VERSION ""

NS_ :

BS_:

BU_: data_logger drive_controller kart_machine_manager motec_ecu

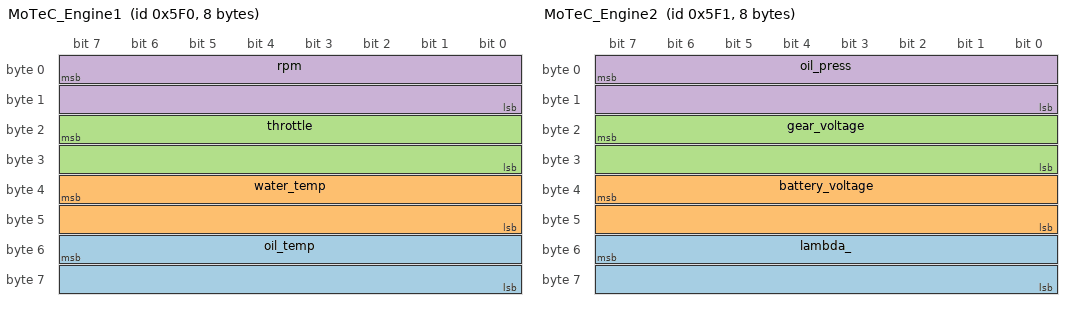
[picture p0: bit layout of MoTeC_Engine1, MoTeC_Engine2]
BO_ 1520 MoTeC_Engine1: 8 motec_ecu
 SG_ oil_temp : 55|16@0+ (0.1,0) [0|0] "degC"  kart_machine_manager
 SG_ water_temp : 39|16@0+ (0.1,0) [0|0] "degC"  kart_machine_manager
 SG_ throttle : 23|16@0+ (0.1,0) [0|0] "%"  kart_machine_manager
 SG_ rpm : 7|16@0+ (1,0) [0|0] "rpm"  kart_machine_manager

BO_ 1521 MoTeC_Engine2: 8 motec_ecu
 SG_ lambda_ : 55|16@0+ (0.001,0) [0|0] ""  kart_machine_manager,drive_controller
 SG_ battery_voltage : 39|16@0+ (0.01,0) [0|0] "V"  kart_machine_manager,drive_controller
 SG_ gear_voltage : 23|16@0+ (0.001,0) [0|0] "V"  kart_machine_manager,drive_controller
 SG_ oil_press : 7|16@0+ (0.1,0) [0|0] ""  kart_machine_manager,drive_controller

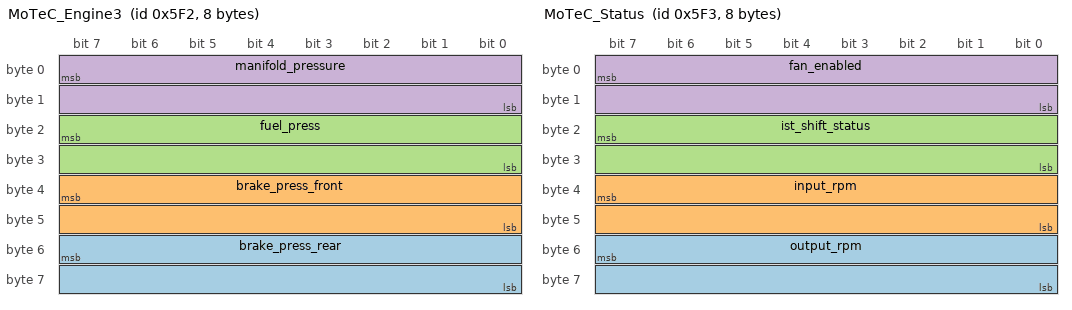
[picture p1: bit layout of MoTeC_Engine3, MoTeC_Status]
BO_ 1522 MoTeC_Engine3: 8 motec_ecu
 SG_ brake_press_rear : 55|16@0+ (0.1,0) [0|0] ""  kart_machine_manager
 SG_ brake_press_front : 39|16@0+ (0.1,0) [0|0] ""  kart_machine_manager
 SG_ fuel_press : 23|16@0+ (0.1,0) [0|0] ""  kart_machine_manager
 SG_ manifold_pressure : 7|16@0+ (0.1,0) [0|0] "kPa"  kart_machine_manager

BO_ 1523 MoTeC_Status: 8 motec_ecu
 SG_ output_rpm : 55|16@0+ (1,0) [0|0] "rpm"  kart_machine_manager
 SG_ input_rpm : 39|16@0+ (1,0) [0|0] "rpm"  kart_machine_manager
 SG_ ist_shift_status : 23|16@0+ (1,0) [0|0] ""  kart_machine_manager
 SG_ fan_enabled : 7|16@0+ (1,0) [0|0] ""  kart_machine_manager

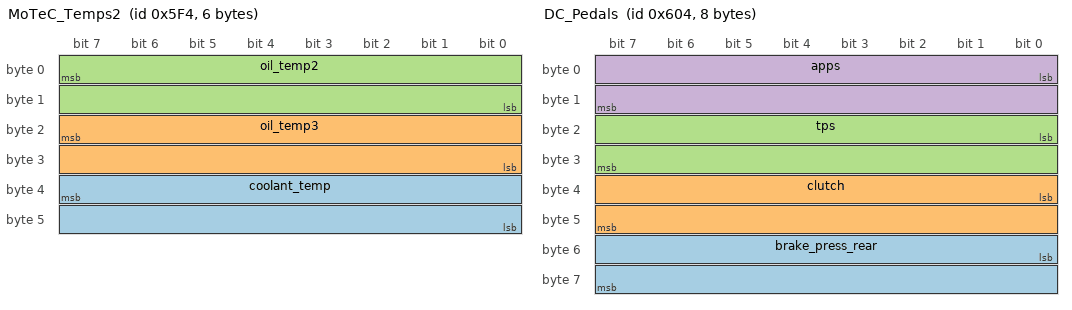
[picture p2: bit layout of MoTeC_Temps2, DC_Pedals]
BO_ 1524 MoTeC_Temps2: 6 motec_ecu
 SG_ coolant_temp : 39|16@0+ (0.1,0) [0|0] "degC"  kart_machine_manager
 SG_ oil_temp3 : 23|16@0+ (0.1,0) [0|0] "degC"  kart_machine_manager
 SG_ oil_temp2 : 7|16@0+ (0.1,0) [0|0] "degC"  kart_machine_manager

BO_ 1536 DC_GyroXY: 8 drive_controller
 SG_ gyro_y : 32|32@1+ (1,0) [0|0] "dps"  kart_machine_manager
 SG_ gyro_x : 0|32@1+ (1,0) [0|0] "dps"  kart_machine_manager

BO_ 1537 DC_GyroZGear: 5 drive_controller
 SG_ gear : 32|8@1+ (1,0) [0|0] ""  kart_machine_manager
 SG_ gyro_z : 0|32@1+ (1,0) [0|0] "dps"  kart_machine_manager

BO_ 1538 DC_AccelXY: 8 drive_controller
 SG_ accel_y : 32|32@1+ (1,0) [0|0] "mg"  kart_machine_manager
 SG_ accel_x : 0|32@1+ (1,0) [0|0] "mg"  kart_machine_manager

BO_ 1539 DC_AccelZ: 4 drive_controller
 SG_ accel_z : 0|32@1+ (1,0) [0|0] "mg"  kart_machine_manager

BO_ 1540 DC_Pedals: 8 drive_controller
 SG_ brake_press_rear : 48|16@1+ (0.1,0) [0|0] "psi"  kart_machine_manager
 SG_ clutch : 32|16@1+ (0.01,0) [0|0] "%"  kart_machine_manager
 SG_ tps : 16|16@1+ (0.01,0) [0|0] "%"  kart_machine_manager
 SG_ apps : 0|16@1+ (0.01,0) [0|0] "%"  kart_machine_manager

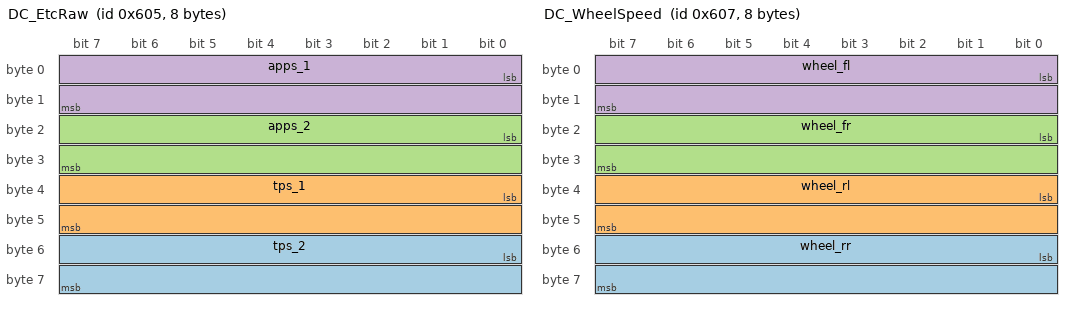
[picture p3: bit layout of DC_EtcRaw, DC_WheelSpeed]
BO_ 1541 DC_EtcRaw: 8 drive_controller
 SG_ tps_2 : 48|16@1+ (7.8125e-05,0) [0|0] "V"  kart_machine_manager
 SG_ tps_1 : 32|16@1+ (7.8125e-05,0) [0|0] "V"  kart_machine_manager
 SG_ apps_2 : 16|16@1+ (7.8125e-05,0) [0|0] "V"  kart_machine_manager
 SG_ apps_1 : 0|16@1+ (7.8125e-05,0) [0|0] "V"  kart_machine_manager

BO_ 1542 DC_StrokeRear: 4 drive_controller
 SG_ stroke_rr : 16|16@1+ (0.01,0) [0|0] "V"  kart_machine_manager
 SG_ stroke_rl : 0|16@1+ (0.01,0) [0|0] "V"  kart_machine_manager

BO_ 1543 DC_WheelSpeed: 8 drive_controller
 SG_ wheel_rr : 48|16@1+ (0.01,0) [0|0] "km/h"  kart_machine_manager
 SG_ wheel_rl : 32|16@1+ (0.01,0) [0|0] "km/h"  kart_machine_manager
 SG_ wheel_fr : 16|16@1+ (0.01,0) [0|0] "km/h"  kart_machine_manager
 SG_ wheel_fl : 0|16@1+ (0.01,0) [0|0] "km/h"  kart_machine_manager

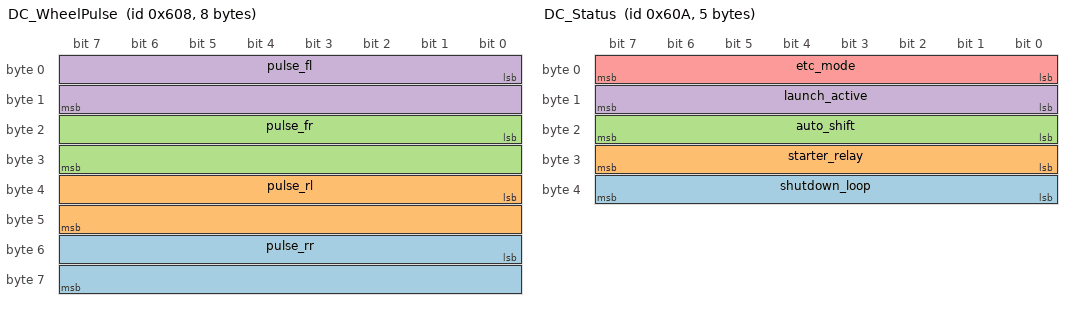
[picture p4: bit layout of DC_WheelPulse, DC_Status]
BO_ 1544 DC_WheelPulse: 8 drive_controller
 SG_ pulse_rr : 48|16@1+ (1,0) [0|0] "count"  kart_machine_manager
 SG_ pulse_rl : 32|16@1+ (1,0) [0|0] "count"  kart_machine_manager
 SG_ pulse_fr : 16|16@1+ (1,0) [0|0] "count"  kart_machine_manager
 SG_ pulse_fl : 0|16@1+ (1,0) [0|0] "count"  kart_machine_manager

BO_ 1545 DC_Engine: 4 drive_controller
 SG_ clutch_rpm : 16|16@1+ (1,0) [0|0] "rpm"  kart_machine_manager
 SG_ engine_rpm : 0|16@1+ (1,0) [0|0] "rpm"  kart_machine_manager

BO_ 1546 DC_Status: 5 drive_controller
 SG_ shutdown_loop : 32|8@1+ (1,0) [0|0] ""  kart_machine_manager
 SG_ starter_relay : 24|8@1+ (1,0) [0|0] ""  kart_machine_manager
 SG_ auto_shift : 16|8@1+ (1,0) [0|0] ""  kart_machine_manager
 SG_ launch_active : 8|8@1+ (1,0) [0|0] ""  kart_machine_manager
 SG_ etc_mode : 0|8@1+ (1,0) [0|0] ""  kart_machine_manager

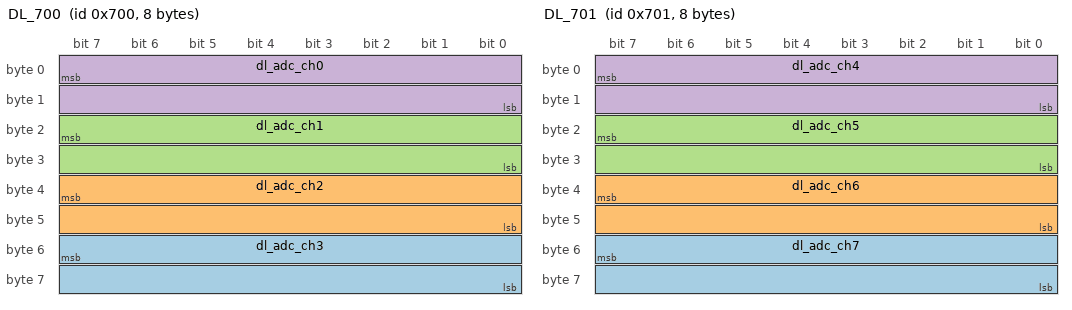
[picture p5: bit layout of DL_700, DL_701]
BO_ 1792 DL_700: 8 data_logger
 SG_ dl_adc_ch3 : 55|16@0+ (7.8125e-05,0) [0|0] "V"  kart_machine_manager
 SG_ dl_adc_ch2 : 39|16@0+ (7.8125e-05,0) [0|0] "V"  kart_machine_manager
 SG_ dl_adc_ch1 : 23|16@0+ (7.8125e-05,0) [0|0] "V"  kart_machine_manager
 SG_ dl_adc_ch0 : 7|16@0+ (7.8125e-05,0) [0|0] "V"  kart_machine_manager

BO_ 1793 DL_701: 8 data_logger
 SG_ dl_adc_ch7 : 55|16@0+ (7.8125e-05,0) [0|0] "V"  kart_machine_manager
 SG_ dl_adc_ch6 : 39|16@0+ (7.8125e-05,0) [0|0] "V"  kart_machine_manager
 SG_ dl_adc_ch5 : 23|16@0+ (7.8125e-05,0) [0|0] "V"  kart_machine_manager
 SG_ dl_adc_ch4 : 7|16@0+ (7.8125e-05,0) [0|0] "V"  kart_machine_manager

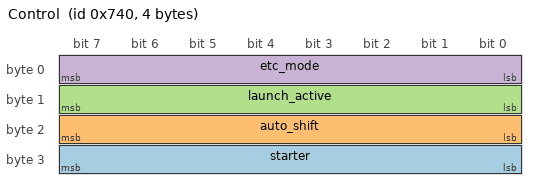
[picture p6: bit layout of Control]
BO_ 1856 Control: 4 data_logger
 SG_ starter : 31|8@0+ (1,0) [0|0] ""  drive_controller,kart_machine_manager
 SG_ auto_shift : 23|8@0+ (1,0) [0|0] ""  drive_controller,kart_machine_manager
 SG_ launch_active : 15|8@0+ (1,0) [0|0] ""  drive_controller,kart_machine_manager
 SG_ etc_mode : 7|8@0+ (1,0) [0|0] ""  drive_controller,kart_machine_manager

BO_ 1857 Shift: 2 data_logger
 SG_ shift_down : 15|8@0+ (1,0) [0|0] ""  drive_controller,kart_machine_manager
 SG_ shift_up : 7|8@0+ (1,0) [0|0] ""  drive_controller,kart_machine_manager

CM_ BU_ data_logger "kmm M コア (Cortex-M4, data-logger-zephyr apps/can-gw)。ADS8688 ADC とコックピットスイッチを送信。Linux 向け CAN ゲートウェイ。";
CM_ BU_ drive_controller "駆動系ECU (Teensy 4.1, 車両後方)。ETC/クラッチ/シフト/セルモーター/ブレーキランプ制御。IMU・APPS/TPS・後方センサー・車輪速・自身の状態を送信。";
CM_ BU_ kart_machine_manager "kmm A コア (Linux)。M コアのゲートウェイ経由で CAN 全受信。インパネ表示・ログ・クラウド送信。実バスへ送信しない。";
CM_ BU_ motec_ecu "[外部ノード] MoTeC M800 エンジンECU（外部）。エンジンデータを送信。";
CM_ BO_ 1521 "battery_voltage は drive_controller が Vbat として使用";
CM_ SG_ 1523 ist_shift_status "(istUp,istDown): 0=なし,1=DOWN,2=UP,3=両方";
CM_ BO_ 1536 "IMU (IAM-20680HP) ジャイロ X/Y";
CM_ BO_ 1537 "IMU ジャイロ Z + ギア位置";
CM_ SG_ 1537 gear "0xFF=不明, 0=N, 1-6=段";
CM_ BO_ 1538 "IMU 加速度 X/Y (単位要確認: 旧実装は mg)";
CM_ BO_ 1539 "IMU 加速度 Z";
CM_ BO_ 1540 "ペダル・スロットル・クラッチ・後ろブレーキ圧 (drive_controller が算出した物理値)";
CM_ SG_ 1540 brake_press_rear "後ろブレーキ圧";
CM_ SG_ 1540 clutch "クラッチ位置";
CM_ SG_ 1540 tps "スロットル開度 (TPS 2 系統から算出)";
CM_ SG_ 1540 apps "採用したアクセルペダル開度 (APPS 2 系統から算出)";
CM_ BO_ 1541 "APPS / TPS 各 2 系統の生値 (drive_controller の ADS8688 カウント)";
CM_ BO_ 1542 "後ろ左右サスペンションストローク (センサー電圧)";
CM_ BO_ 1543 "車輪速 4 輪";
CM_ BO_ 1544 "車輪速パルスの生カウント 4 輪 (累積、uint16 でラップ)";
CM_ BO_ 1545 "エンジン回転数 (drive_controller のパルス計測値)";
CM_ SG_ 1545 clutch_rpm "クラッチ後 (出力軸) 回転数";
CM_ BO_ 1546 "drive_controller が適用中の制御状態とリレー状態";
CM_ SG_ 1546 shutdown_loop "Shutdown Circuit (AND 回路) の出力状態";
CM_ SG_ 1546 starter_relay "セルモーターリレー出力";
CM_ SG_ 1546 etc_mode "適用中の ETC モード";
CM_ BO_ 1792 "data-logger 生バッファ byte 0-7（再構成の一部）";
CM_ BO_ 1793 "data-logger 生バッファ byte 8-15（再構成の一部）";
CM_ BO_ 1856 "コックピットスイッチ状態 (ETC モード / ローンチ / オートシフト / セル)";
CM_ SG_ 1856 starter "セルスイッチ。押下中 1";
CM_ SG_ 1856 auto_shift "オートシフト ON/OFF スイッチ";
CM_ SG_ 1856 launch_active "ローンチコントロール ON/OFF スイッチ";
CM_ SG_ 1856 etc_mode "ETC モード選択スイッチ。0=未指定";
CM_ BO_ 1857 "シフトパドル状態";
CM_ SG_ 1857 shift_down "シフトダウンパドル。押下中 1";
CM_ SG_ 1857 shift_up "シフトアップパドル。押下中 1";
BA_DEF_ BO_  "GenMsgCycleTime" INT 0 65535;
BA_DEF_DEF_  "GenMsgCycleTime" 0;
BA_ "GenMsgCycleTime" BO_ 1536 16;
BA_ "GenMsgCycleTime" BO_ 1537 16;
BA_ "GenMsgCycleTime" BO_ 1538 16;
BA_ "GenMsgCycleTime" BO_ 1539 16;
BA_ "GenMsgCycleTime" BO_ 1540 20;
BA_ "GenMsgCycleTime" BO_ 1541 20;
BA_ "GenMsgCycleTime" BO_ 1542 20;
BA_ "GenMsgCycleTime" BO_ 1543 20;
BA_ "GenMsgCycleTime" BO_ 1544 20;
BA_ "GenMsgCycleTime" BO_ 1545 20;
BA_ "GenMsgCycleTime" BO_ 1546 33;
BA_ "GenMsgCycleTime" BO_ 1792 33;
BA_ "GenMsgCycleTime" BO_ 1793 33;
BA_ "GenMsgCycleTime" BO_ 1856 33;
BA_ "GenMsgCycleTime" BO_ 1857 10;
VAL_ 1523 ist_shift_status 0 "NONE" 1 "DOWN" 2 "UP" 3 "BOTH" ;
VAL_ 1523 fan_enabled 0 "OFF" 1 "ON" ;
VAL_ 1546 shutdown_loop 0 "OPEN" 1 "CLOSED" ;
VAL_ 1546 starter_relay 0 "OFF" 1 "ON" ;
VAL_ 1546 auto_shift 0 "MANUAL" 1 "AUTO" ;
VAL_ 1546 launch_active 0 "INACTIVE" 1 "ACTIVE" ;
VAL_ 1546 etc_mode 1 "CALIB" 2 "NORMAL" 3 "RESTRICTED" 4 "MOTOR_OFF" ;
VAL_ 1856 starter 0 "OFF" 1 "ON" ;
VAL_ 1856 auto_shift 0 "MANUAL" 1 "AUTO" ;
VAL_ 1856 launch_active 0 "INACTIVE" 1 "ACTIVE" ;
VAL_ 1856 etc_mode 1 "CALIB" 2 "NORMAL" 3 "RESTRICTED" 4 "MOTOR_OFF" ;
VAL_ 1857 shift_down 0 "RELEASED" 1 "PRESSED" ;
VAL_ 1857 shift_up 0 "RELEASED" 1 "PRESSED" ;
SIG_VALTYPE_ 1536 gyro_x : 1;
SIG_VALTYPE_ 1536 gyro_y : 1;
SIG_VALTYPE_ 1537 gyro_z : 1;
SIG_VALTYPE_ 1538 accel_x : 1;
SIG_VALTYPE_ 1538 accel_y : 1;
SIG_VALTYPE_ 1539 accel_z : 1;
